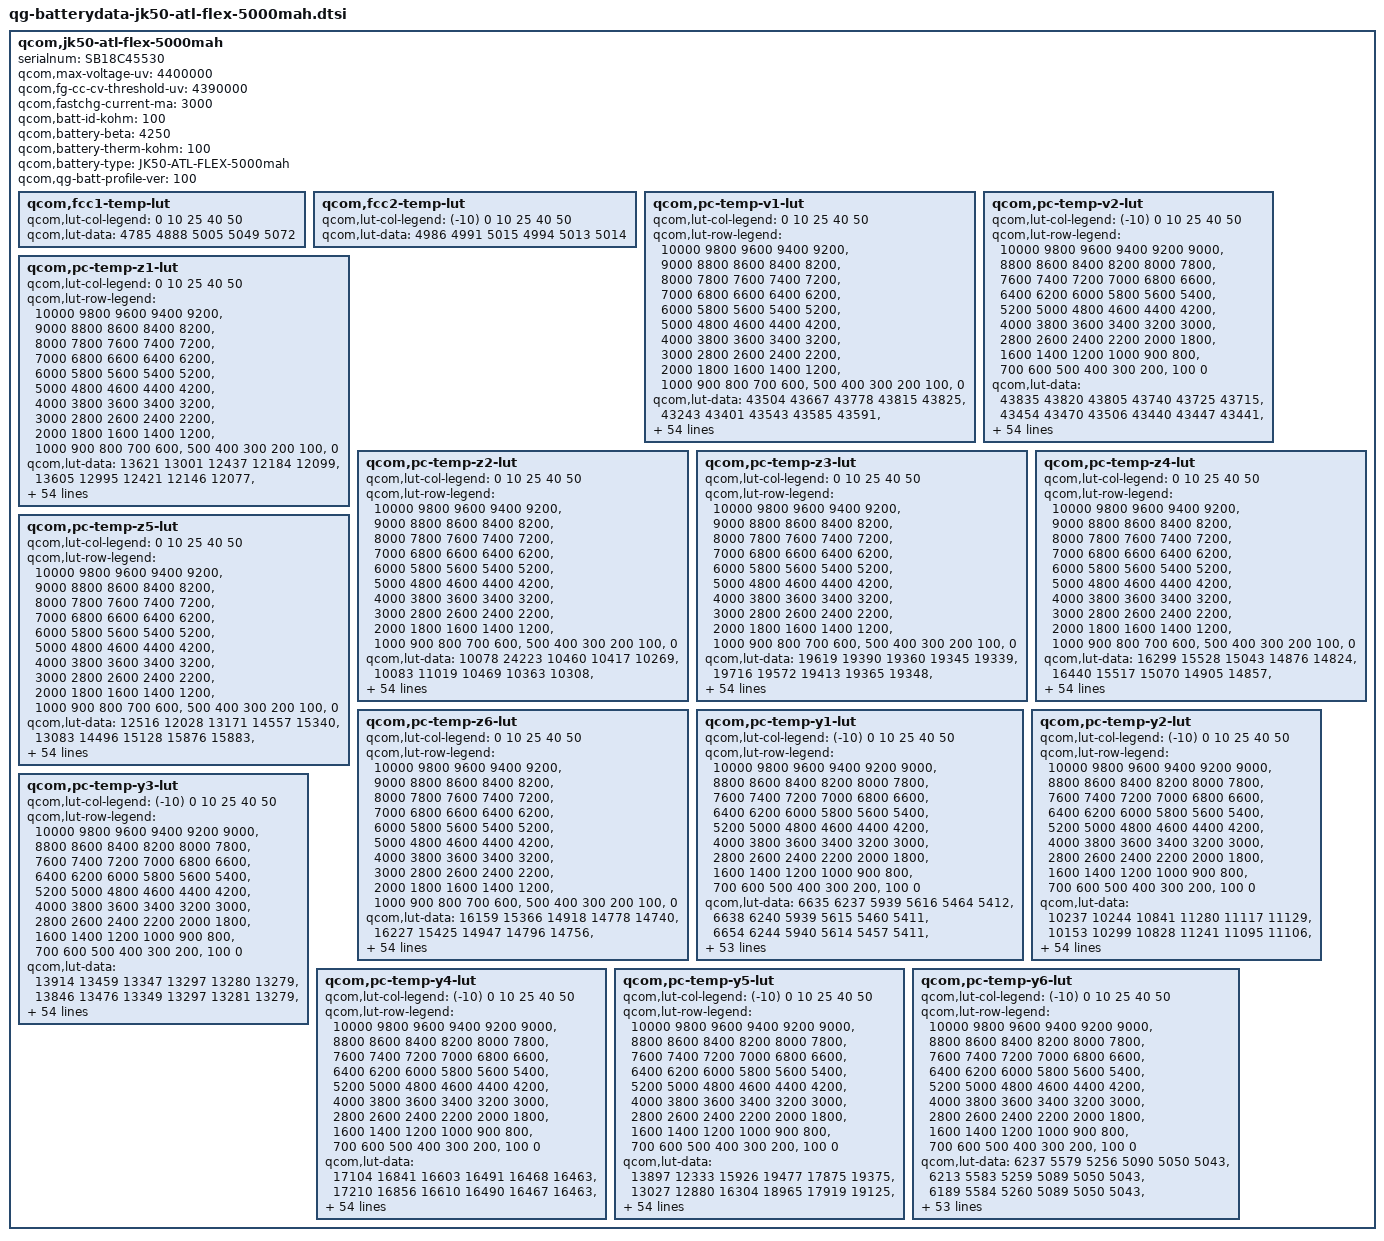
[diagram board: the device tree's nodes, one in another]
qcom,jk50-atl-flex-5000mah {
    /* 3489914_Wingtech_OsloATL_5000mAh_averaged_MasterSlave_Jul3rd2018 */
    serialnum = "SB18C45530";
    qcom,max-voltage-uv = <4400000>;
    qcom,fg-cc-cv-threshold-uv = <4390000>;
    qcom,fastchg-current-ma = <3000>;
    qcom,batt-id-kohm = <100>;
    qcom,battery-beta = <4250>;
    qcom,battery-therm-kohm = <100>;
    qcom,battery-type = "JK50-ATL-FLEX-5000mah";
    qcom,qg-batt-profile-ver = <100>;

	qcom,fcc1-temp-lut {
		qcom,lut-col-legend = <0 10 25 40 50>;
		qcom,lut-data = <4785 4888 5005 5049 5072>;
	};

	qcom,fcc2-temp-lut {
		qcom,lut-col-legend = <(-10) 0 10 25 40 50>;
		qcom,lut-data = <4986 4991 5015 4994 5013 5014>;
	};

	qcom,pc-temp-v1-lut {
		qcom,lut-col-legend = <0 10 25 40 50>;
		qcom,lut-row-legend = <10000 9800 9600 9400 9200>,
			<9000 8800 8600 8400 8200>,
			<8000 7800 7600 7400 7200>,
			<7000 6800 6600 6400 6200>,
			<6000 5800 5600 5400 5200>,
			<5000 4800 4600 4400 4200>,
			<4000 3800 3600 3400 3200>,
			<3000 2800 2600 2400 2200>,
			<2000 1800 1600 1400 1200>,
			<1000 900 800 700 600>,
			<500 400 300 200 100>,
			<0>;
		qcom,lut-data = <43504 43667 43778 43815 43825>,
			<43243 43401 43543 43585 43591>,
			<42991 43149 43300 43355 43365>,
			<42748 42910 43059 43124 43140>,
			<42512 42676 42821 42892 42911>,
			<42284 42444 42584 42658 42678>,
			<42061 42214 42350 42426 42446>,
			<41843 41988 42117 42192 42213>,
			<41631 41766 41889 41963 41983>,
			<41428 41550 41664 41737 41756>,
			<41232 41342 41445 41514 41532>,
			<41036 41143 41234 41296 41312>,
			<40832 40945 41031 41081 41096>,
			<40625 40747 40828 40873 40887>,
			<40406 40544 40620 40668 40682>,
			<40175 40332 40417 40469 40484>,
			<39973 40118 40221 40279 40295>,
			<39821 39939 40037 40101 40115>,
			<39692 39798 39876 39932 39944>,
			<39566 39668 39743 39782 39789>,
			<39440 39532 39591 39627 39633>,
			<39319 39394 39365 39413 39426>,
			<39199 39235 39103 39130 39154>,
			<39081 39013 38904 38916 38937>,
			<38966 38782 38748 38792 38809>,
			<38850 38630 38629 38693 38707>,
			<38737 38520 38547 38598 38605>,
			<38631 38439 38483 38510 38504>,
			<38527 38386 38419 38425 38410>,
			<38438 38345 38354 38339 38324>,
			<38372 38305 38293 38260 38246>,
			<38316 38267 38237 38190 38175>,
			<38270 38230 38185 38128 38110>,
			<38232 38196 38136 38070 38048>,
			<38198 38164 38091 38020 37991>,
			<38166 38129 38047 37971 37935>,
			<38137 38096 38007 37924 37877>,
			<38100 38055 37967 37876 37820>,
			<38048 37995 37908 37814 37748>,
			<37979 37910 37817 37724 37653>,
			<37891 37811 37712 37619 37546>,
			<37765 37695 37603 37510 37433>,
			<37626 37560 37477 37386 37307>,
			<37475 37399 37319 37233 37151>,
			<37331 37257 37176 37092 37018>,
			<37242 37165 37079 37001 36938>,
			<37207 37135 37052 36970 36907>,
			<37181 37111 37033 36952 36889>,
			<37159 37093 37015 36931 36866>,
			<37101 37046 36963 36872 36793>,
			<36888 36815 36718 36610 36501>,
			<36437 36368 36280 36163 36057>,
			<35859 35797 35703 35576 35480>,
			<35075 35010 34917 34788 34688>,
			<33829 33772 33686 33557 33451>,
			<30000 30000 30000 30000 30000>;
	};

	qcom,pc-temp-v2-lut {
		qcom,lut-col-legend = <(-10) 0 10 25 40 50>;
		qcom,lut-row-legend = <10000 9800 9600 9400 9200 9000>,
			<8800 8600 8400 8200 8000 7800>,
			<7600 7400 7200 7000 6800 6600>,
			<6400 6200 6000 5800 5600 5400>,
			<5200 5000 4800 4600 4400 4200>,
			<4000 3800 3600 3400 3200 3000>,
			<2800 2600 2400 2200 2000 1800>,
			<1600 1400 1200 1000 900 800>,
			<700 600 500 400 300 200>,
			<100 0>;
		qcom,lut-data = <43835 43820 43805 43740 43725 43715>,
			<43454 43470 43506 43440 43447 43441>,
			<43108 43150 43224 43160 43182 43179>,
			<42798 42864 42960 42900 42930 42930>,
			<42517 42611 42714 42660 42692 42695>,
			<42271 42368 42474 42426 42458 42462>,
			<42073 42123 42235 42192 42224 42228>,
			<41891 41884 42000 41961 41991 41995>,
			<41656 41651 41771 41733 41763 41767>,
			<41346 41420 41547 41507 41536 41541>,
			<41104 41207 41329 41287 41314 41318>,
			<41000 41034 41123 41076 41098 41100>,
			<40917 40871 40922 40871 40885 40885>,
			<40714 40661 40718 40667 40680 40680>,
			<40211 40392 40512 40460 40479 40479>,
			<39760 40117 40299 40259 40286 40287>,
			<39542 39851 40076 40066 40097 40102>,
			<39380 39597 39851 39882 39917 39924>,
			<39221 39395 39632 39715 39749 39757>,
			<39072 39231 39416 39570 39599 39603>,
			<38922 39076 39217 39407 39428 39431>,
			<38751 38917 39032 39177 39199 39202>,
			<38577 38763 38864 38925 38957 38962>,
			<38439 38618 38714 38741 38775 38781>,
			<38328 38473 38581 38601 38628 38634>,
			<38238 38340 38462 38481 38503 38509>,
			<38163 38215 38355 38373 38393 38398>,
			<38097 38107 38257 38277 38296 38299>,
			<38036 38035 38164 38188 38207 38208>,
			<37979 37983 38074 38107 38128 38124>,
			<37923 37937 37993 38033 38056 38050>,
			<37867 37894 37920 37966 37990 37983>,
			<37812 37852 37857 37905 37929 37921>,
			<37757 37807 37810 37845 37864 37854>,
			<37704 37762 37775 37790 37796 37783>,
			<37649 37715 37737 37735 37721 37700>,
			<37586 37666 37696 37675 37630 37594>,
			<37520 37614 37651 37613 37535 37481>,
			<37451 37550 37595 37544 37453 37391>,
			<37378 37474 37528 37469 37380 37316>,
			<37306 37390 37448 37387 37302 37237>,
			<37238 37292 37344 37293 37210 37148>,
			<37170 37186 37222 37181 37101 37041>,
			<37102 37078 37088 37048 36969 36907>,
			<37024 36972 36970 36932 36863 36806>,
			<36926 36877 36881 36871 36812 36759>,
			<36865 36824 36850 36853 36800 36749>,
			<36793 36768 36816 36833 36785 36732>,
			<36700 36704 36767 36803 36755 36698>,
			<36539 36602 36671 36719 36655 36581>,
			<36248 36401 36427 36455 36337 36238>,
			<35794 35992 35963 35966 35842 35735>,
			<35164 35373 35320 35334 35191 35080>,
			<34274 34499 34448 34494 34300 34170>,
			<32940 33174 33129 33176 33008 32865>,
			<28459 27934 27956 27761 27790 27703>;
	};

	qcom,pc-temp-z1-lut {
		qcom,lut-col-legend = <0 10 25 40 50>;
		qcom,lut-row-legend = <10000 9800 9600 9400 9200>,
			<9000 8800 8600 8400 8200>,
			<8000 7800 7600 7400 7200>,
			<7000 6800 6600 6400 6200>,
			<6000 5800 5600 5400 5200>,
			<5000 4800 4600 4400 4200>,
			<4000 3800 3600 3400 3200>,
			<3000 2800 2600 2400 2200>,
			<2000 1800 1600 1400 1200>,
			<1000 900 800 700 600>,
			<500 400 300 200 100>,
			<0>;
		qcom,lut-data = <13621 13001 12437 12184 12099>,
			<13605 12995 12421 12146 12077>,
			<13604 12972 12406 12133 12068>,
			<13601 12947 12389 12124 12061>,
			<13586 12933 12374 12118 12057>,
			<13567 12927 12362 12113 12054>,
			<13557 12922 12351 12109 12052>,
			<13553 12914 12341 12104 12051>,
			<13550 12901 12335 12102 12051>,
			<13553 12890 12331 12103 12053>,
			<13556 12884 12328 12104 12056>,
			<13549 12881 12327 12106 12060>,
			<13518 12873 12326 12110 12063>,
			<13481 12853 12326 12112 12065>,
			<13463 12833 12325 12111 12066>,
			<13451 12827 12324 12109 12066>,
			<13442 12823 12323 12109 12067>,
			<13426 12822 12323 12111 12068>,
			<13406 12821 12325 12113 12069>,
			<13401 12821 12329 12115 12071>,
			<13425 12827 12334 12117 12072>,
			<13450 12839 12338 12119 12074>,
			<13441 12845 12341 12119 12074>,
			<13408 12840 12345 12121 12075>,
			<13391 12834 12349 12123 12077>,
			<13398 12837 12354 12126 12079>,
			<13411 12855 12358 12130 12082>,
			<13425 12868 12363 12133 12085>,
			<13448 12868 12367 12137 12089>,
			<13463 12867 12372 12142 12093>,
			<13459 12869 12376 12147 12097>,
			<13450 12874 12383 12151 12100>,
			<13444 12878 12390 12155 12104>,
			<13439 12879 12397 12160 12107>,
			<13434 12880 12404 12164 12111>,
			<13436 12883 12411 12169 12115>,
			<13443 12902 12418 12173 12118>,
			<13452 12922 12425 12176 12121>,
			<13463 12928 12431 12180 12124>,
			<13477 12929 12437 12185 12128>,
			<13494 12931 12443 12190 12132>,
			<13522 12942 12451 12195 12135>,
			<13543 12953 12458 12200 12138>,
			<13562 12959 12470 12203 12142>,
			<13560 12960 12482 12209 12146>,
			<13540 12979 12476 12213 12147>,
			<13549 12996 12481 12215 12148>,
			<13541 12978 12480 12213 12148>,
			<13511 12966 12482 12217 12151>,
			<13533 12968 12490 12222 12155>,
			<13559 12976 12495 12227 12161>,
			<13536 13008 12509 12236 12169>,
			<13587 13040 12529 12246 12181>,
			<13613 13061 12556 12266 12194>,
			<13613 13061 12556 12266 12194>,
			<13613 13061 12556 12266 12194>;
	};

	qcom,pc-temp-z2-lut {
		qcom,lut-col-legend = <0 10 25 40 50>;
		qcom,lut-row-legend = <10000 9800 9600 9400 9200>,
			<9000 8800 8600 8400 8200>,
			<8000 7800 7600 7400 7200>,
			<7000 6800 6600 6400 6200>,
			<6000 5800 5600 5400 5200>,
			<5000 4800 4600 4400 4200>,
			<4000 3800 3600 3400 3200>,
			<3000 2800 2600 2400 2200>,
			<2000 1800 1600 1400 1200>,
			<1000 900 800 700 600>,
			<500 400 300 200 100>,
			<0>;
		qcom,lut-data = <10078 24223 10460 10417 10269>,
			<10083 11019 10469 10363 10308>,
			<10174 10328 10509 10479 10384>,
			<10252 10320 10521 10574 10451>,
			<10276 10307 10502 10576 10501>,
			<10292 10286 10476 10558 10547>,
			<10300 10260 10451 10538 10563>,
			<10307 10241 10429 10517 10545>,
			<10310 10226 10419 10499 10517>,
			<10307 10218 10410 10476 10490>,
			<10296 10214 10403 10455 10462>,
			<10282 10213 10395 10456 10442>,
			<10258 10232 10389 10464 10426>,
			<10226 10335 10393 10467 10408>,
			<10199 10408 10420 10476 10362>,
			<10170 10364 10444 10495 10303>,
			<10156 10290 10455 10474 10289>,
			<10157 10283 10463 10366 10299>,
			<10160 10311 10475 10303 10315>,
			<10162 10344 10495 10316 10337>,
			<10160 10373 10524 10349 10371>,
			<10158 10402 10594 10454 10476>,
			<10162 10426 10676 10708 10757>,
			<10169 10446 10682 10824 10910>,
			<10176 10461 10608 10632 10724>,
			<10186 10470 10549 10402 10470>,
			<10200 10478 10543 10385 10458>,
			<10215 10481 10540 10415 10608>,
			<10233 10477 10545 10460 10716>,
			<10248 10469 10575 10578 10705>,
			<10257 10468 10600 10687 10641>,
			<10263 10471 10608 10677 10560>,
			<10271 10475 10613 10622 10448>,
			<10279 10479 10617 10588 10384>,
			<10288 10484 10619 10571 10343>,
			<10299 10490 10623 10562 10318>,
			<10311 10499 10630 10572 10339>,
			<10326 10511 10642 10607 10404>,
			<10344 10525 10662 10642 10467>,
			<10364 10544 10703 10698 10538>,
			<10381 10554 10731 10741 10584>,
			<10394 10557 10729 10741 10574>,
			<10416 10562 10726 10736 10554>,
			<10465 10582 10737 10727 10581>,
			<10747 10737 10800 10693 10561>,
			<10676 10811 10821 10629 10515>,
			<10683 10813 10812 10633 10525>,
			<10625 10817 10807 10632 10520>,
			<10514 10913 10827 10642 10559>,
			<10476 11016 10876 10749 10642>,
			<10503 11015 10893 10646 10478>,
			<10418 10933 10813 10427 10286>,
			<10174 10739 10764 10414 10235>,
			<9990 10587 10650 10352 10174>,
			<9990 10587 10650 10352 10174>,
			<9990 10587 10650 10352 10174>;
	};

	qcom,pc-temp-z3-lut {
		qcom,lut-col-legend = <0 10 25 40 50>;
		qcom,lut-row-legend = <10000 9800 9600 9400 9200>,
			<9000 8800 8600 8400 8200>,
			<8000 7800 7600 7400 7200>,
			<7000 6800 6600 6400 6200>,
			<6000 5800 5600 5400 5200>,
			<5000 4800 4600 4400 4200>,
			<4000 3800 3600 3400 3200>,
			<3000 2800 2600 2400 2200>,
			<2000 1800 1600 1400 1200>,
			<1000 900 800 700 600>,
			<500 400 300 200 100>,
			<0>;
		qcom,lut-data = <19619 19390 19360 19345 19339>,
			<19716 19572 19413 19365 19348>,
			<19765 19618 19450 19385 19366>,
			<19783 19633 19464 19396 19378>,
			<19773 19638 19467 19401 19385>,
			<19748 19635 19468 19405 19392>,
			<19731 19632 19468 19407 19396>,
			<19714 19630 19467 19408 19399>,
			<19703 19627 19466 19408 19399>,
			<19704 19622 19465 19406 19398>,
			<19710 19616 19462 19402 19397>,
			<19713 19609 19456 19399 19394>,
			<19721 19606 19448 19395 19389>,
			<19733 19607 19442 19392 19383>,
			<19743 19606 19438 19391 19379>,
			<19755 19594 19436 19390 19375>,
			<19762 19575 19434 19387 19372>,
			<19750 19559 19432 19379 19368>,
			<19727 19543 19428 19371 19363>,
			<19717 19531 19419 19365 19356>,
			<19718 19531 19415 19361 19350>,
			<19721 19533 19425 19364 19351>,
			<19724 19537 19444 19378 19362>,
			<19728 19551 19447 19385 19368>,
			<19730 19567 19438 19370 19353>,
			<19734 19569 19428 19351 19333>,
			<19738 19568 19421 19348 19335>,
			<19738 19566 19415 19348 19360>,
			<19737 19562 19414 19351 19380>,
			<19734 19556 19416 19369 19389>,
			<19728 19550 19420 19390 19393>,
			<19718 19545 19426 19395 19389>,
			<19709 19541 19432 19396 19383>,
			<19700 19537 19433 19396 19376>,
			<19690 19534 19433 19390 19368>,
			<19678 19530 19433 19382 19360>,
			<19664 19526 19428 19375 19355>,
			<19652 19523 19421 19369 19351>,
			<19642 19520 19418 19366 19349>,
			<19633 19517 19417 19365 19347>,
			<19628 19514 19417 19364 19346>,
			<19624 19508 19412 19363 19348>,
			<19617 19502 19407 19363 19352>,
			<19597 19497 19404 19363 19355>,
			<19525 19466 19396 19361 19355>,
			<19407 19435 19383 19347 19341>,
			<19398 19429 19379 19346 19339>,
			<19379 19423 19373 19336 19330>,
			<19319 19374 19361 19335 19324>,
			<19317 19356 19352 19327 19320>,
			<19331 19369 19358 19346 19348>,
			<19344 19398 19370 19361 19358>,
			<19349 19339 19374 19357 19353>,
			<19350 19339 19364 19349 19352>,
			<19350 19339 19364 19349 19352>,
			<19350 19339 19364 19349 19352>;
	};

	qcom,pc-temp-z4-lut {
		qcom,lut-col-legend = <0 10 25 40 50>;
		qcom,lut-row-legend = <10000 9800 9600 9400 9200>,
			<9000 8800 8600 8400 8200>,
			<8000 7800 7600 7400 7200>,
			<7000 6800 6600 6400 6200>,
			<6000 5800 5600 5400 5200>,
			<5000 4800 4600 4400 4200>,
			<4000 3800 3600 3400 3200>,
			<3000 2800 2600 2400 2200>,
			<2000 1800 1600 1400 1200>,
			<1000 900 800 700 600>,
			<500 400 300 200 100>,
			<0>;
		qcom,lut-data = <16299 15528 15043 14876 14824>,
			<16440 15517 15070 14905 14857>,
			<16262 15450 15039 14892 14852>,
			<16065 15301 14998 14871 14840>,
			<15899 15166 14943 14848 14823>,
			<15744 15081 14893 14822 14802>,
			<15621 15013 14858 14801 14783>,
			<15521 14958 14828 14783 14767>,
			<15433 14912 14803 14767 14753>,
			<15353 14875 14781 14753 14740>,
			<15281 14849 14763 14741 14728>,
			<15216 14825 14749 14730 14718>,
			<15154 14800 14737 14719 14711>,
			<15098 14766 14729 14710 14705>,
			<15054 14745 14724 14702 14701>,
			<15018 14747 14719 14696 14697>,
			<14986 14756 14712 14693 14694>,
			<14958 14753 14703 14692 14689>,
			<14933 14743 14694 14690 14685>,
			<14907 14731 14684 14685 14682>,
			<14876 14721 14679 14681 14679>,
			<14847 14710 14704 14697 14693>,
			<14823 14707 14755 14760 14751>,
			<14802 14744 14792 14803 14795>,
			<14789 14798 14820 14817 14811>,
			<14781 14816 14834 14826 14820>,
			<14775 14822 14828 14823 14812>,
			<14775 14825 14812 14807 14771>,
			<14781 14816 14797 14786 14737>,
			<14785 14798 14781 14754 14715>,
			<14784 14783 14764 14722 14699>,
			<14783 14771 14746 14705 14691>,
			<14781 14759 14728 14693 14686>,
			<14776 14748 14716 14688 14683>,
			<14769 14737 14707 14687 14684>,
			<14765 14727 14701 14686 14684>,
			<14760 14718 14697 14686 14685>,
			<14756 14712 14695 14686 14685>,
			<14749 14711 14696 14687 14687>,
			<14743 14712 14702 14696 14698>,
			<14740 14712 14706 14703 14707>,
			<14737 14711 14703 14700 14701>,
			<14733 14710 14699 14692 14692>,
			<14727 14705 14695 14691 14690>,
			<14715 14688 14679 14683 14680>,
			<14811 14688 14667 14669 14665>,
			<14817 14686 14663 14663 14660>,
			<14835 14683 14657 14658 14653>,
			<14892 14732 14658 14640 14638>,
			<14887 14746 14664 14643 14635>,
			<14870 14737 14678 14656 14650>,
			<14877 14721 14676 14656 14654>,
			<14890 14794 14675 14664 14663>,
			<14905 14805 14691 14676 14668>,
			<14905 14805 14691 14676 14668>,
			<14905 14805 14691 14676 14668>;
	};

	qcom,pc-temp-z5-lut {
		qcom,lut-col-legend = <0 10 25 40 50>;
		qcom,lut-row-legend = <10000 9800 9600 9400 9200>,
			<9000 8800 8600 8400 8200>,
			<8000 7800 7600 7400 7200>,
			<7000 6800 6600 6400 6200>,
			<6000 5800 5600 5400 5200>,
			<5000 4800 4600 4400 4200>,
			<4000 3800 3600 3400 3200>,
			<3000 2800 2600 2400 2200>,
			<2000 1800 1600 1400 1200>,
			<1000 900 800 700 600>,
			<500 400 300 200 100>,
			<0>;
		qcom,lut-data = <12516 12028 13171 14557 15340>,
			<13083 14496 15128 15876 15883>,
			<13611 15595 16739 17483 17408>,
			<13984 16175 17623 18522 18532>,
			<14196 16565 18049 18972 19382>,
			<14338 16913 18422 19303 20230>,
			<14417 17279 18857 19761 21046>,
			<14482 17773 19346 20337 21802>,
			<14554 18431 19982 20660 22402>,
			<14728 19095 20877 20805 22972>,
			<15037 19662 21464 20959 23508>,
			<15326 20279 21540 21342 23764>,
			<15624 21388 21572 22155 23892>,
			<16006 23830 21720 23001 24070>,
			<16577 25513 22272 24148 24426>,
			<17464 25056 23024 25306 24901>,
			<17968 23966 23999 25275 25380>,
			<17924 23626 25094 24047 25867>,
			<17803 23587 25968 23288 25974>,
			<17838 23589 26897 23782 25719>,
			<18786 24623 28494 24913 25467>,
			<20284 28799 41188 28295 26570>,
			<21916 34743 60001 36366 31122>,
			<24118 47132 62085 39933 33491>,
			<26842 60356 47931 31525 26846>,
			<30956 61641 34749 20973 18236>,
			<35531 55852 29138 18537 17557>,
			<39059 49505 25455 17621 20554>,
			<42661 44512 24581 17457 22657>,
			<44741 40037 24456 20012 24899>,
			<43922 37300 24466 24132 27228>,
			<41903 35459 25872 27965 28136>,
			<40140 34358 28944 32060 29439>,
			<38159 33950 32158 34082 30135>,
			<35871 33871 36211 34887 29984>,
			<33506 34058 38449 35282 29680>,
			<30889 34556 37786 34774 29643>,
			<29153 35174 36499 33294 29629>,
			<28838 35831 35964 32047 29314>,
			<29074 36535 35884 30845 27276>,
			<29409 36669 35654 29535 25516>,
			<31227 33984 32743 27871 25378>,
			<31802 32288 29317 26441 25577>,
			<30574 33140 29085 26824 27330>,
			<27779 32347 30499 27001 28124>,
			<18758 26323 29266 23825 23582>,
			<16862 24406 27268 23361 22723>,
			<15676 23683 25507 20810 20928>,
			<12396 18717 23080 23785 22603>,
			<12426 15510 21205 21077 22070>,
			<12947 17589 19917 22641 26224>,
			<13087 17848 20049 23262 24391>,
			<12849 13604 19998 20198 19944>,
			<12552 13165 17366 16923 17643>,
			<12552 13165 17366 16923 17643>,
			<12552 13165 17366 16923 17643>;
	};

	qcom,pc-temp-z6-lut {
		qcom,lut-col-legend = <0 10 25 40 50>;
		qcom,lut-row-legend = <10000 9800 9600 9400 9200>,
			<9000 8800 8600 8400 8200>,
			<8000 7800 7600 7400 7200>,
			<7000 6800 6600 6400 6200>,
			<6000 5800 5600 5400 5200>,
			<5000 4800 4600 4400 4200>,
			<4000 3800 3600 3400 3200>,
			<3000 2800 2600 2400 2200>,
			<2000 1800 1600 1400 1200>,
			<1000 900 800 700 600>,
			<500 400 300 200 100>,
			<0>;
		qcom,lut-data = <16159 15366 14918 14778 14740>,
			<16227 15425 14947 14796 14756>,
			<16144 15413 14947 14797 14761>,
			<16044 15344 14936 14793 14760>,
			<15944 15271 14912 14786 14756>,
			<15842 15222 14887 14775 14751>,
			<15761 15182 14869 14767 14746>,
			<15695 15149 14854 14760 14740>,
			<15640 15121 14841 14753 14735>,
			<15596 15097 14830 14746 14730>,
			<15559 15079 14820 14739 14724>,
			<15524 15062 14810 14733 14719>,
			<15488 15045 14800 14727 14713>,
			<15456 15024 14793 14721 14708>,
			<15433 15007 14789 14717 14703>,
			<15416 14997 14784 14713 14700>,
			<15399 14989 14780 14709 14696>,
			<15377 14979 14775 14704 14692>,
			<15353 14967 14769 14700 14687>,
			<15335 14957 14761 14694 14682>,
			<15320 14955 14757 14690 14677>,
			<15309 14954 14774 14700 14685>,
			<15300 14954 14807 14737 14718>,
			<15292 14977 14823 14756 14737>,
			<15288 15010 14831 14753 14735>,
			<15287 15020 14834 14749 14731>,
			<15287 15024 14830 14745 14728>,
			<15289 15025 14821 14739 14725>,
			<15292 15021 14814 14735 14722>,
			<15293 15011 14810 14732 14718>,
			<15291 15003 14806 14729 14714>,
			<15285 14997 14802 14726 14709>,
			<15280 14991 14799 14722 14704>,
			<15276 14986 14796 14719 14700>,
			<15271 14981 14794 14716 14696>,
			<15266 14977 14791 14712 14692>,
			<15259 14974 14788 14709 14690>,
			<15255 14972 14785 14706 14687>,
			<15253 14973 14785 14705 14687>,
			<15252 14976 14789 14708 14691>,
			<15253 14977 14791 14712 14694>,
			<15257 14978 14789 14710 14694>,
			<15258 14979 14787 14708 14692>,
			<15255 14979 14786 14708 14693>,
			<15226 14965 14779 14704 14690>,
			<15213 14953 14768 14692 14676>,
			<15211 14949 14765 14688 14673>,
			<15207 14945 14759 14681 14665>,
			<15203 14942 14754 14673 14655>,
			<15205 14942 14753 14671 14652>,
			<15212 14950 14765 14688 14675>,
			<15231 14964 14773 14697 14685>,
			<15251 14975 14779 14702 14689>,
			<15278 14994 14787 14707 14694>,
			<15278 14994 14787 14707 14694>,
			<15278 14994 14787 14707 14694>;
	};

	qcom,pc-temp-y1-lut {
		qcom,lut-col-legend = <(-10) 0 10 25 40 50>;
		qcom,lut-row-legend = <10000 9800 9600 9400 9200 9000>,
			<8800 8600 8400 8200 8000 7800>,
			<7600 7400 7200 7000 6800 6600>,
			<6400 6200 6000 5800 5600 5400>,
			<5200 5000 4800 4600 4400 4200>,
			<4000 3800 3600 3400 3200 3000>,
			<2800 2600 2400 2200 2000 1800>,
			<1600 1400 1200 1000 900 800>,
			<700 600 500 400 300 200>,
			<100 0>;
		qcom,lut-data = <6635 6237 5939 5616 5464 5412>,
			<6638 6240 5939 5615 5460 5411>,
			<6654 6244 5940 5614 5457 5411>,
			<6675 6248 5940 5613 5454 5410>,
			<6693 6251 5939 5612 5451 5409>,
			<6701 6252 5936 5611 5449 5409>,
			<6713 6251 5931 5609 5448 5408>,
			<6733 6249 5926 5607 5447 5408>,
			<6735 6253 5925 5605 5446 5408>,
			<6720 6262 5925 5603 5445 5407>,
			<6709 6268 5926 5602 5445 5406>,
			<6714 6263 5925 5602 5444 5406>,
			<6723 6254 5924 5603 5444 5406>,
			<6727 6252 5922 5603 5443 5406>,
			<6730 6264 5917 5604 5442 5406>,
			<6731 6274 5915 5604 5442 5406>,
			<6726 6279 5919 5605 5443 5407>,
			<6717 6283 5926 5606 5446 5408>,
			<6712 6281 5930 5606 5446 5409>,
			<6711 6277 5935 5608 5447 5409>,
			<6710 6273 5938 5609 5447 5410>,
			<6701 6273 5934 5612 5448 5411>,
			<6691 6278 5928 5616 5450 5411>,
			<6693 6282 5927 5621 5452 5412>,
			<6701 6285 5933 5625 5454 5414>,
			<6707 6282 5939 5629 5457 5416>,
			<6714 6277 5943 5632 5460 5418>,
			<6725 6272 5946 5637 5463 5420>,
			<6722 6268 5950 5641 5466 5422>,
			<6687 6265 5956 5646 5469 5425>,
			<6660 6263 5959 5650 5472 5428>,
			<6652 6262 5956 5656 5477 5430>,
			<6646 6262 5949 5664 5481 5433>,
			<6649 6263 5950 5669 5484 5436>,
			<6674 6267 5958 5672 5487 5438>,
			<6694 6270 5964 5675 5489 5440>,
			<6694 6273 5959 5677 5491 5442>,
			<6681 6274 5952 5680 5492 5444>,
			<6673 6272 5954 5681 5494 5445>,
			<6673 6262 5964 5681 5495 5447>,
			<6677 6257 5971 5681 5497 5448>,
			<6681 6262 5980 5687 5499 5449>,
			<6681 6260 5989 5692 5501 5451>,
			<6663 6246 5985 5692 5504 5454>,
			<6671 6263 5979 5706 5511 5459>,
			<6731 6260 5986 5719 5513 5460>,
			<6703 6295 5990 5717 5512 5459>,
			<6713 6290 6002 5718 5513 5459>,
			<6723 6299 5982 5719 5512 5459>,
			<6707 6289 5989 5718 5511 5461>,
			<6719 6305 5991 5719 5514 5463>,
			<6741 6305 6001 5736 5523 5469>,
			<6736 6312 6024 5756 5532 5476>,
			<6839 6329 6043 5775 5543 5487>,
			<6839 6329 6043 5775 5543 5487>,
			<6839 6329 6043 5775 5543 5487>;
	};

	qcom,pc-temp-y2-lut {
		qcom,lut-col-legend = <(-10) 0 10 25 40 50>;
		qcom,lut-row-legend = <10000 9800 9600 9400 9200 9000>,
			<8800 8600 8400 8200 8000 7800>,
			<7600 7400 7200 7000 6800 6600>,
			<6400 6200 6000 5800 5600 5400>,
			<5200 5000 4800 4600 4400 4200>,
			<4000 3800 3600 3400 3200 3000>,
			<2800 2600 2400 2200 2000 1800>,
			<1600 1400 1200 1000 900 800>,
			<700 600 500 400 300 200>,
			<100 0>;
		qcom,lut-data = <10237 10244 10841 11280 11117 11129>,
			<10153 10299 10828 11241 11095 11106>,
			<10119 10349 10814 11203 11070 11077>,
			<10124 10390 10802 11167 11045 11045>,
			<10155 10419 10790 11134 11024 11014>,
			<10202 10433 10780 11103 11008 10987>,
			<10291 10426 10770 11076 10995 10957>,
			<10406 10412 10762 11051 10980 10931>,
			<10474 10424 10762 11030 10966 10927>,
			<10538 10505 10773 11010 10948 10942>,
			<10568 10584 10786 11000 10938 10951>,
			<10589 10667 10798 11003 10964 10945>,
			<10630 10757 10815 11008 11006 10938>,
			<10621 10784 10860 11020 11014 10933>,
			<10428 10806 10974 11057 11007 10927>,
			<10255 10834 11052 11104 11005 10933>,
			<10041 10868 11072 11160 11029 10959>,
			<9754 10911 11085 11227 11081 11000>,
			<9700 10965 11099 11293 11165 11071>,
			<9694 11045 11115 11368 11317 11207>,
			<9689 11103 11134 11404 11398 11278>,
			<9685 11112 11162 11385 11366 11219>,
			<9681 11103 11194 11353 11303 11140>,
			<9677 11081 11226 11348 11261 11134>,
			<9675 11049 11260 11368 11227 11163>,
			<9673 11018 11288 11393 11214 11193>,
			<9671 10883 11315 11421 11231 11219>,
			<9670 10602 11336 11453 11268 11243>,
			<9669 10459 11338 11478 11308 11268>,
			<9668 10403 11333 11507 11362 11319>,
			<9667 10364 11326 11532 11422 11381>,
			<9666 10344 11321 11552 11499 11455>,
			<9665 10322 11313 11566 11561 11535>,
			<9665 10205 11301 11565 11573 11565>,
			<9664 9875 11285 11545 11572 11553>,
			<9663 9707 11265 11526 11561 11510>,
			<9663 9691 11235 11515 11477 11420>,
			<9663 9682 11200 11506 11365 11310>,
			<9662 9677 11168 11486 11351 11254>,
			<9662 9673 11133 11448 11389 11217>,
			<9661 9670 11087 11415 11414 11214>,
			<9661 9667 11024 11391 11400 11286>,
			<9661 9664 10947 11365 11373 11331>,
			<9660 9662 10865 11327 11318 11193>,
			<9660 9661 10692 11266 11236 11034>,
			<9660 9661 10441 11254 11130 10967>,
			<9660 9660 10364 11239 11161 10989>,
			<9660 9660 10278 11237 11204 11031>,
			<9659 9659 10237 11239 11202 11039>,
			<9659 9659 10206 11246 11207 11026>,
			<9658 9658 10139 11203 11172 10941>,
			<9657 9657 9754 11107 11052 10863>,
			<9656 9657 9689 11030 10960 10764>,
			<9653 9656 9669 10949 10862 10612>,
			<9653 9656 9669 10949 10862 10612>,
			<9653 9656 9669 10949 10862 10612>;
	};

	qcom,pc-temp-y3-lut {
		qcom,lut-col-legend = <(-10) 0 10 25 40 50>;
		qcom,lut-row-legend = <10000 9800 9600 9400 9200 9000>,
			<8800 8600 8400 8200 8000 7800>,
			<7600 7400 7200 7000 6800 6600>,
			<6400 6200 6000 5800 5600 5400>,
			<5200 5000 4800 4600 4400 4200>,
			<4000 3800 3600 3400 3200 3000>,
			<2800 2600 2400 2200 2000 1800>,
			<1600 1400 1200 1000 900 800>,
			<700 600 500 400 300 200>,
			<100 0>;
		qcom,lut-data = <13914 13459 13347 13297 13280 13279>,
			<13846 13476 13349 13297 13281 13279>,
			<13791 13487 13352 13296 13281 13279>,
			<13750 13492 13354 13297 13282 13280>,
			<13725 13494 13356 13297 13282 13280>,
			<13716 13495 13358 13298 13283 13280>,
			<13732 13489 13360 13299 13283 13281>,
			<13758 13480 13362 13300 13284 13282>,
			<13738 13481 13362 13300 13284 13282>,
			<13595 13494 13362 13300 13285 13283>,
			<13497 13502 13362 13300 13285 13284>,
			<13506 13473 13363 13302 13287 13284>,
			<13524 13424 13363 13306 13290 13284>,
			<13525 13416 13362 13307 13292 13285>,
			<13501 13429 13358 13308 13292 13286>,
			<13477 13439 13355 13308 13293 13287>,
			<13460 13428 13354 13307 13293 13288>,
			<13447 13406 13353 13305 13294 13288>,
			<13446 13394 13351 13305 13294 13289>,
			<13457 13386 13343 13308 13293 13291>,
			<13467 13379 13337 13309 13292 13291>,
			<13464 13368 13332 13306 13290 13287>,
			<13457 13358 13328 13299 13286 13281>,
			<13452 13355 13325 13296 13283 13279>,
			<13449 13355 13323 13294 13282 13278>,
			<13450 13354 13321 13293 13281 13278>,
			<13460 13344 13320 13292 13280 13278>,
			<13476 13331 13319 13292 13279 13278>,
			<13492 13329 13318 13292 13279 13277>,
			<13510 13336 13318 13291 13280 13277>,
			<13529 13345 13318 13292 13280 13277>,
			<13550 13349 13315 13292 13281 13277>,
			<13574 13353 13312 13293 13282 13278>,
			<13601 13358 13312 13293 13282 13279>,
			<13630 13366 13316 13293 13282 13279>,
			<13661 13376 13319 13293 13282 13279>,
			<13691 13389 13320 13293 13281 13278>,
			<13723 13404 13322 13293 13280 13277>,
			<13759 13423 13323 13293 13280 13277>,
			<13798 13447 13326 13293 13282 13279>,
			<13838 13477 13327 13293 13283 13281>,
			<13881 13517 13328 13295 13283 13282>,
			<13928 13568 13328 13296 13283 13282>,
			<13983 13633 13329 13295 13281 13280>,
			<14036 13710 13331 13296 13281 13280>,
			<14023 13735 13329 13298 13284 13285>,
			<14028 13754 13335 13299 13288 13288>,
			<14096 13815 13344 13303 13292 13290>,
			<14165 13882 13358 13309 13295 13291>,
			<14249 13937 13372 13311 13294 13290>,
			<14357 14001 13384 13309 13290 13285>,
			<14518 14081 13406 13308 13291 13287>,
			<14845 14228 13448 13314 13294 13292>,
			<15675 14470 13560 13326 13302 13299>,
			<15675 14470 13560 13326 13302 13299>,
			<15675 14470 13560 13326 13302 13299>;
	};

	qcom,pc-temp-y4-lut {
		qcom,lut-col-legend = <(-10) 0 10 25 40 50>;
		qcom,lut-row-legend = <10000 9800 9600 9400 9200 9000>,
			<8800 8600 8400 8200 8000 7800>,
			<7600 7400 7200 7000 6800 6600>,
			<6400 6200 6000 5800 5600 5400>,
			<5200 5000 4800 4600 4400 4200>,
			<4000 3800 3600 3400 3200 3000>,
			<2800 2600 2400 2200 2000 1800>,
			<1600 1400 1200 1000 900 800>,
			<700 600 500 400 300 200>,
			<100 0>;
		qcom,lut-data = <17104 16841 16603 16491 16468 16463>,
			<17210 16856 16610 16490 16467 16463>,
			<17274 16869 16617 16491 16466 16463>,
			<17306 16882 16623 16491 16466 16463>,
			<17316 16894 16628 16493 16467 16463>,
			<17316 16906 16630 16494 16467 16464>,
			<17248 16918 16629 16496 16468 16464>,
			<17143 16929 16628 16498 16470 16464>,
			<17151 16925 16629 16501 16473 16465>,
			<17334 16893 16638 16509 16477 16467>,
			<17477 16872 16650 16516 16480 16470>,
			<17499 16973 16662 16519 16481 16473>,
			<17504 17137 16678 16523 16483 16477>,
			<17440 17153 16706 16530 16486 16480>,
			<17162 17038 16757 16548 16493 16484>,
			<16971 16920 16784 16568 16502 16488>,
			<16976 16849 16761 16586 16511 16494>,
			<16997 16795 16719 16603 16523 16503>,
			<16983 16774 16677 16619 16542 16517>,
			<16933 16765 16632 16635 16575 16542>,
			<16875 16754 16598 16641 16591 16554>,
			<16819 16737 16576 16594 16557 16532>,
			<16768 16715 16560 16515 16502 16497>,
			<16749 16685 16552 16488 16480 16479>,
			<16743 16633 16547 16480 16468 16468>,
			<16739 16593 16544 16477 16464 16464>,
			<16737 16587 16543 16478 16466 16465>,
			<16736 16591 16542 16482 16470 16467>,
			<16735 16594 16538 16486 16475 16471>,
			<16737 16595 16526 16491 16482 16478>,
			<16740 16598 16518 16496 16489 16486>,
			<16741 16604 16516 16500 16499 16495>,
			<16743 16613 16517 16504 16508 16504>,
			<16743 16626 16521 16505 16509 16508>,
			<16740 16650 16530 16505 16507 16509>,
			<16737 16668 16540 16504 16503 16507>,
			<16738 16678 16552 16501 16488 16490>,
			<16740 16685 16564 16494 16470 16469>,
			<16742 16689 16573 16493 16468 16467>,
			<16748 16690 16581 16494 16470 16470>,
			<16755 16690 16586 16496 16474 16475>,
			<16767 16685 16587 16501 16479 16481>,
			<16788 16678 16585 16505 16480 16482>,
			<16817 16676 16577 16500 16468 16465>,
			<16839 16683 16578 16497 16460 16454>,
			<16818 16685 16583 16498 16469 16469>,
			<16806 16694 16599 16507 16488 16495>,
			<16826 16725 16629 16529 16516 16527>,
			<16841 16767 16671 16563 16551 16560>,
			<16846 16810 16719 16584 16553 16550>,
			<16834 16823 16724 16561 16487 16484>,
			<16819 16803 16721 16533 16476 16475>,
			<16840 16781 16743 16547 16482 16477>,
			<17107 16792 16805 16592 16509 16495>,
			<17107 16792 16805 16592 16509 16495>,
			<17107 16792 16805 16592 16509 16495>;
	};

	qcom,pc-temp-y5-lut {
		qcom,lut-col-legend = <(-10) 0 10 25 40 50>;
		qcom,lut-row-legend = <10000 9800 9600 9400 9200 9000>,
			<8800 8600 8400 8200 8000 7800>,
			<7600 7400 7200 7000 6800 6600>,
			<6400 6200 6000 5800 5600 5400>,
			<5200 5000 4800 4600 4400 4200>,
			<4000 3800 3600 3400 3200 3000>,
			<2800 2600 2400 2200 2000 1800>,
			<1600 1400 1200 1000 900 800>,
			<700 600 500 400 300 200>,
			<100 0>;
		qcom,lut-data = <13897 12333 15926 19477 17875 19375>,
			<13027 12880 16304 18965 17919 19125>,
			<12628 13585 16645 18472 17789 18815>,
			<12620 14289 16926 18014 17565 18491>,
			<12923 14832 17129 17608 17331 18200>,
			<13458 15054 17231 17272 17168 17987>,
			<15991 14964 17231 17024 16948 17726>,
			<19490 14822 17170 16805 16597 17438>,
			<19461 14933 17048 16433 16237 17264>,
			<15280 15661 16751 15636 15805 17001>,
			<12422 16134 16416 15141 15592 16745>,
			<14897 15601 15980 15309 16084 16333>,
			<19001 14764 15548 15602 16796 15835>,
			<19649 15430 15621 15568 16769 15607>,
			<17701 20010 16520 15033 16056 15650>,
			<15989 23108 17860 14682 15515 15754>,
			<15016 21211 20776 14824 15342 15581>,
			<13997 18110 23886 15241 15238 15259>,
			<14224 17581 24023 16508 15285 15263>,
			<15611 18327 22668 20589 15730 15543>,
			<16613 19047 21751 23360 16425 16001>,
			<16113 19441 21251 23611 18760 17208>,
			<14894 19846 20781 23685 21311 18590>,
			<14130 20742 20494 23358 21444 19022>,
			<13359 22766 20091 21987 20577 19207>,
			<12962 23926 20109 20939 19647 19270>,
			<12967 20695 20561 20555 18546 18739>,
			<12987 15315 21208 20251 17539 17748>,
			<13037 14154 22137 20114 17407 17082>,
			<13124 14738 23448 20126 17638 16472>,
			<13146 15301 23925 20409 17989 16281>,
			<13161 15753 21980 21557 18585 16620>,
			<13236 16074 19395 22965 19385 17311>,
			<13385 15780 19255 23516 20425 18431>,
			<13749 14721 20411 23829 21860 20221>,
			<14013 14307 21064 23962 22508 21060>,
			<13950 14487 20961 23601 21750 20734>,
			<13820 14665 20816 22942 20682 20160>,
			<13734 14685 20773 22184 20716 20275>,
			<13496 14658 20763 20964 21553 21099>,
			<13228 14615 20723 20108 21962 21643>,
			<13156 14514 20162 20097 21283 21717>,
			<13145 14396 19312 19992 20469 21607>,
			<13302 14244 18743 19241 19332 20514>,
			<13575 13999 18082 18571 18438 19726>,
			<13830 14208 16138 18574 17226 17895>,
			<13886 14105 16103 18126 17858 17648>,
			<14074 14070 16077 18128 17891 16979>,
			<14550 14490 16615 18591 17664 16480>,
			<14767 14895 17344 19009 17259 15966>,
			<14478 15344 17471 19256 19191 16591>,
			<14140 14707 15610 19637 19920 16953>,
			<13961 13985 14453 20103 19877 18717>,
			<12802 13598 14170 22258 24505 24056>,
			<12802 13598 14170 22258 24505 24056>,
			<12802 13598 14170 22258 24505 24056>;
	};

	qcom,pc-temp-y6-lut {
		qcom,lut-col-legend = <(-10) 0 10 25 40 50>;
		qcom,lut-row-legend = <10000 9800 9600 9400 9200 9000>,
			<8800 8600 8400 8200 8000 7800>,
			<7600 7400 7200 7000 6800 6600>,
			<6400 6200 6000 5800 5600 5400>,
			<5200 5000 4800 4600 4400 4200>,
			<4000 3800 3600 3400 3200 3000>,
			<2800 2600 2400 2200 2000 1800>,
			<1600 1400 1200 1000 900 800>,
			<700 600 500 400 300 200>,
			<100 0>;
		qcom,lut-data = <6237 5579 5256 5090 5050 5043>,
			<6213 5583 5259 5089 5050 5043>,
			<6189 5584 5260 5089 5050 5043>,
			<6167 5584 5260 5089 5050 5043>,
			<6148 5583 5259 5090 5050 5044>,
			<6134 5581 5258 5090 5051 5044>,
			<6124 5577 5255 5091 5052 5045>,
			<6116 5570 5252 5092 5053 5045>,
			<6097 5565 5251 5093 5054 5046>,
			<6054 5561 5251 5094 5055 5047>,
			<6028 5559 5252 5096 5056 5049>,
			<6041 5567 5254 5098 5058 5050>,
			<6063 5580 5257 5101 5060 5051>,
			<6051 5580 5262 5105 5063 5053>,
			<5955 5561 5272 5111 5065 5055>,
			<5882 5537 5277 5116 5068 5057>,
			<5873 5512 5271 5120 5071 5059>,
			<5869 5486 5259 5124 5074 5062>,
			<5865 5477 5245 5129 5080 5067>,
			<5862 5472 5227 5135 5089 5074>,
			<5859 5469 5213 5137 5093 5078>,
			<5851 5463 5204 5122 5081 5069>,
			<5839 5458 5197 5095 5062 5053>,
			<5837 5454 5194 5086 5054 5047>,
			<5842 5449 5193 5083 5049 5043>,
			<5851 5445 5193 5081 5048 5042>,
			<5865 5445 5194 5082 5048 5042>,
			<5883 5447 5196 5084 5049 5043>,
			<5901 5455 5197 5085 5050 5044>,
			<5919 5474 5197 5087 5053 5046>,
			<5937 5494 5198 5090 5056 5048>,
			<5956 5514 5199 5092 5060 5052>,
			<5978 5535 5202 5095 5063 5055>,
			<6000 5557 5207 5097 5064 5057>,
			<6023 5580 5217 5098 5064 5057>,
			<6048 5606 5228 5099 5063 5057>,
			<6074 5633 5239 5098 5058 5052>,
			<6101 5663 5251 5098 5052 5045>,
			<6131 5696 5264 5098 5052 5044>,
			<6162 5731 5278 5099 5054 5047>,
			<6196 5771 5292 5101 5057 5050>,
			<6233 5815 5308 5105 5059 5053>,
			<6274 5864 5324 5108 5059 5053>,
			<6325 5923 5344 5108 5055 5047>,
			<6376 5994 5370 5111 5053 5045>,
			<6371 6019 5373 5114 5058 5053>,
			<6377 6041 5395 5118 5067 5063>,
			<6435 6100 5427 5128 5077 5074>,
			<6494 6164 5467 5142 5089 5084>,
			<6561 6221 5505 5150 5089 5080>,
			<6647 6278 5528 5142 5068 5058>,
			<6780 6339 5562 5136 5066 5057>,
			<7061 6452 5649 5152 5071 5063>,
			<7850 6655 5810 5182 5086 5075>,
			<7850 6655 5810 5182 5086 5075>,
			<7850 6655 5810 5182 5086 5075>;
	};

};
